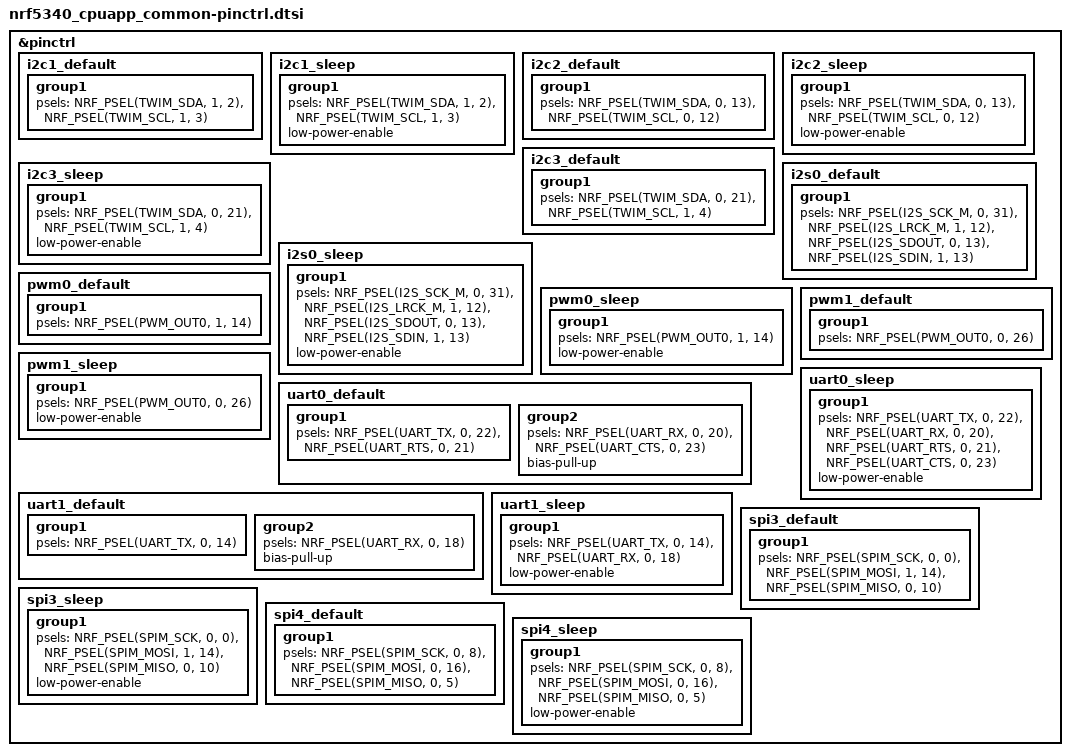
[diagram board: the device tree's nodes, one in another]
/*
 * Copyright (c) 2022 Nordic Semiconductor
 * SPDX-License-Identifier: Apache-2.0
 */

&pinctrl {
	i2c1_default: i2c1_default {
		group1 {
			psels = <NRF_PSEL(TWIM_SDA, 1, 2)>,
				<NRF_PSEL(TWIM_SCL, 1, 3)>;
		};
	};

	i2c1_sleep: i2c1_sleep {
		group1 {
			psels = <NRF_PSEL(TWIM_SDA, 1, 2)>,
				<NRF_PSEL(TWIM_SCL, 1, 3)>;
			low-power-enable;
		};
	};

	i2c2_default: i2c2_default {
		group1 {
			psels = <NRF_PSEL(TWIM_SDA, 0, 13)>,
				<NRF_PSEL(TWIM_SCL, 0, 12)>;
		};
	};

	i2c2_sleep: i2c2_sleep {
		group1 {
			psels = <NRF_PSEL(TWIM_SDA, 0, 13)>,
				<NRF_PSEL(TWIM_SCL, 0, 12)>;
			low-power-enable;
		};
	};

	i2c3_default: i2c3_default {
		group1 {
			psels = <NRF_PSEL(TWIM_SDA, 0, 21)>,
				<NRF_PSEL(TWIM_SCL, 1, 4)>;
		};
	};

	i2c3_sleep: i2c3_sleep {
		group1 {
			psels = <NRF_PSEL(TWIM_SDA, 0, 21)>,
				<NRF_PSEL(TWIM_SCL, 1, 4)>;
			low-power-enable;
		};
	};

	i2s0_default: i2s0_default {
		group1 {
			psels = <NRF_PSEL(I2S_SCK_M, 0, 31)>,
				<NRF_PSEL(I2S_LRCK_M, 1, 12)>,
				<NRF_PSEL(I2S_SDOUT, 0, 13)>,
				<NRF_PSEL(I2S_SDIN, 1, 13)>;
		};
	};

	i2s0_sleep: i2s0_sleep {
		group1 {
			psels = 
				<NRF_PSEL(I2S_SCK_M, 0, 31)>,
				<NRF_PSEL(I2S_LRCK_M, 1, 12)>,
				<NRF_PSEL(I2S_SDOUT, 0, 13)>,
				<NRF_PSEL(I2S_SDIN, 1, 13)>;
			low-power-enable;
		};
	};


	pwm0_default: pwm0_default {
		group1 {
			psels = <NRF_PSEL(PWM_OUT0, 1, 14)>;
		};
	};

	pwm0_sleep: pwm0_sleep {
		group1 {
			psels = <NRF_PSEL(PWM_OUT0, 1, 14)>;
			low-power-enable;
		};
	};

	pwm1_default: pwm1_default {
		group1 {
			psels = <NRF_PSEL(PWM_OUT0, 0, 26)>;
		};
	};

	pwm1_sleep: pwm1_sleep {
		group1 {
			psels = <NRF_PSEL(PWM_OUT0, 0, 26)>;
			low-power-enable;
		};
	};

    uart0_default: uart0_default {
		group1 {
			psels = <NRF_PSEL(UART_TX, 0, 22)>,
				<NRF_PSEL(UART_RTS, 0, 21)>;
		};

		group2 {
			psels = <NRF_PSEL(UART_RX, 0, 20)>,
				<NRF_PSEL(UART_CTS, 0, 23)>;
			bias-pull-up;
		};
	};

	uart0_sleep: uart0_sleep {
		group1 {
			psels = <NRF_PSEL(UART_TX, 0, 22)>,
				<NRF_PSEL(UART_RX, 0, 20)>,
				<NRF_PSEL(UART_RTS, 0, 21)>,
				<NRF_PSEL(UART_CTS, 0, 23)>;
			low-power-enable;
		};
	};

	uart1_default: uart1_default {
		group1 {
			psels = <NRF_PSEL(UART_TX, 0, 14)>;
		};

		group2 {
			psels = <NRF_PSEL(UART_RX, 0, 18)>;
			bias-pull-up;
		};
	};

	uart1_sleep: uart1_sleep {
		group1 {
			psels = <NRF_PSEL(UART_TX, 0, 14)>,
				<NRF_PSEL(UART_RX, 0, 18)>;
			low-power-enable;
		};
	};

	spi3_default: spi3_default {
		group1 {
			psels = <NRF_PSEL(SPIM_SCK, 0, 0)>,
				<NRF_PSEL(SPIM_MOSI, 1, 14)>,
				<NRF_PSEL(SPIM_MISO, 0, 10)>;
			};
	};

	spi3_sleep: spi3_sleep {
		group1 {
			psels = <NRF_PSEL(SPIM_SCK, 0, 0)>,
				<NRF_PSEL(SPIM_MOSI, 1, 14)>,
				<NRF_PSEL(SPIM_MISO, 0, 10)>;
			low-power-enable;
		};
	};

	spi4_default: spi4_default {
		group1 {
			psels = <NRF_PSEL(SPIM_SCK, 0, 8)>,
				<NRF_PSEL(SPIM_MOSI, 0, 16)>,
				<NRF_PSEL(SPIM_MISO, 0, 5)>;
			};
	};

	spi4_sleep: spi4_sleep {
		group1 {
			psels = <NRF_PSEL(SPIM_SCK, 0, 8)>,
				<NRF_PSEL(SPIM_MOSI, 0, 16)>,
				<NRF_PSEL(SPIM_MISO, 0, 5)>;
			low-power-enable;
		};
	};
};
